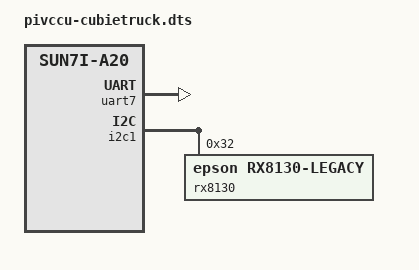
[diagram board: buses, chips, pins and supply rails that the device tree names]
/dts-v1/;
/plugin/;

/ {
        compatible = "allwinner,sun7i-a20";

        fragment@0 {
                target-path = "/aliases";
                __overlay__ {
                        serial7 = "/soc@01c00000/serial@01c29c00";
                };
        };


        fragment@1 {
                target = <&uart7>;
                __overlay__ {
                        pinctrl-names = "default";
                        pinctrl-0 = <&uart7_pins_a>;
                        status = "okay";
                        compatible = "pivccu,dw_apb";
                        pivccu,reset_pin = <&pio 1 15 0>;
                };
        };

        fragment@2 {
                target = <&i2c1>;
                __overlay__ {
                #address-cells = <1>;
                #size-cells = <0>;
                status = "okay";

                rx8130@32 {
                        compatible = "epson,rx8130-legacy";
                        reg = <0x32>;
                        status = "okay";
                        enable-external-capacitor;
                        };
                };
        };
};

